# DA14682 register map
Vendor: Dialog; Series: DA14682; File version: 1.2
CPU: CM0 r1p0, little endian, MPU, FPU, 3 interrupt priority bits
Registers are 16-bit, read-write, reset 0x0 unless marked. A register's access mark holds for its fields unless they carry their own. Offsets are from the block's base; [hi:lo] are bit positions; lines under a group give offsets from that group; {n}, {i} and the like mark numbered series; 'fields as' and 'values as' point back to an identical list.

## KBSCAN — KBSCAN registers
Base 0x50001600
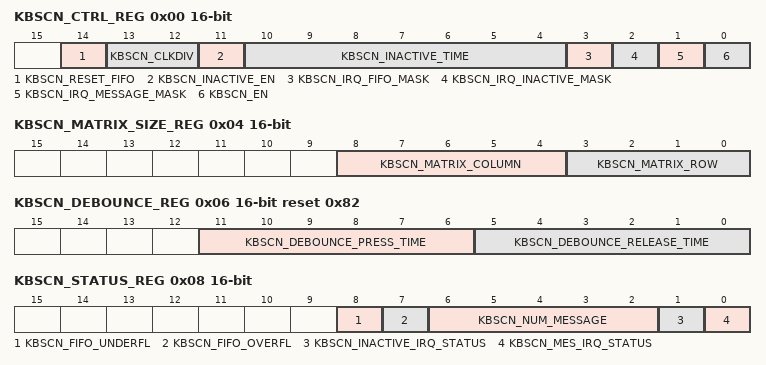
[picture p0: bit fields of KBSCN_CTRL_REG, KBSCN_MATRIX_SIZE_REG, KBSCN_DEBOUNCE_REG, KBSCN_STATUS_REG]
0x00 KBSCN_CTRL_REG — Keyboard scanner control register
  [14] KBSCN_RESET_FIFO wo — '1' reset fifo, read always '0'
  [13:12] KBSCN_CLKDIV — Defines keyboard clk. "00" div/1, "01" div/4, "10" div/16, "11" div/64
  [11] KBSCN_INACTIVE_EN — '1' After inactive time the keyboard scanner stops the key maxtrix scan
  [10:4] KBSCN_INACTIVE_TIME — Defines the inactive time in scan cycles. Value 0 is not allowed
  [3] KBSCN_IRQ_FIFO_MASK — '1' Enable IRQ for fifo over and under flow
  [2] KBSCN_IRQ_INACTIVE_MASK — '1' : Enable IRQ for inactive
  [1] KBSCN_IRQ_MESSAGE_MASK — '1' : Enable IRQ for message
  [0] KBSCN_EN — '1' : Enable keyboard scanner, Auto clear when inactive enable and inactive case
0x02 KBSCN_CTRL2_REG — Keyboard scanner control 2 register
  [15:0] KBSCN_ROW_ACTIVE_TIME — Define the row active time in keyboard clock cycles
0x04 KBSCN_MATRIX_SIZE_REG — Defines the number of rows and columns of the matrix
  [8:4] KBSCN_MATRIX_COLUMN — Defines the number of the columns of the keyboard matrix minus 1. Zero means number of columns 1
  [3:0] KBSCN_MATRIX_ROW — Defines the number of the rows of the keyboard matrix minus 1. Zero means number of rows 1
0x06 KBSCN_DEBOUNCE_REG reset 0x82 — Defines the debounce time for key press and release
  [11:6] KBSCN_DEBOUNCE_PRESS_TIME — Defines the press debounce time in cycles of full matrix scan. One means no debounce, zero is reserved
  [5:0] KBSCN_DEBOUNCE_RELEASE_TIME — Defines the press debounce time in cycles of full matrix scan. One means no debounce, zero is reserved
0x08 KBSCN_STATUS_REG — keyboard scanner Interrupt status register
  [8] KBSCN_FIFO_UNDERFL ro — '1' Fifo Underflow occurred
  [7] KBSCN_FIFO_OVERFL ro — '1' Fifo Overflow occurred
  [6:2] KBSCN_NUM_MESSAGE ro — Defines how many messages there are in the fifo.
  [1] KBSCN_INACTIVE_IRQ_STATUS ro — There is no keyboard activity for a predefined time
  [0] KBSCN_MES_IRQ_STATUS ro — There is at least one last message in the fifo.
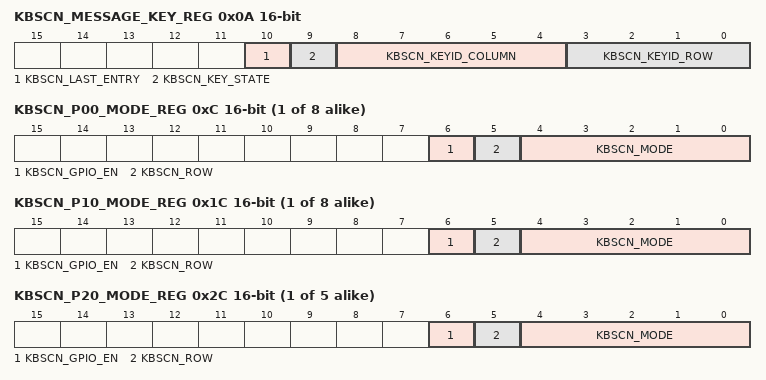
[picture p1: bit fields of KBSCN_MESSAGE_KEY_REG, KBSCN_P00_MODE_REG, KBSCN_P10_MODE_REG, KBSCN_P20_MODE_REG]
0x0A KBSCN_MESSAGE_KEY_REG — Returns a key message from the message queue
  [10] KBSCN_LAST_ENTRY ro — '1' : this message is the last of the group message, else '0'. When '1' bits 9:0 are all '1'
  [9] KBSCN_KEY_STATE ro — '0' : New key state is release '1' : New key state is press
  [8:4] KBSCN_KEYID_COLUMN ro — Defines the column id of key
  [3:0] KBSCN_KEYID_ROW ro — Defines the row id of key
{0xC+2i} KBSCN_P{i:02}_MODE_REG (i=0..7) — Defines the keyboard mode for P{i:02}
  [6] KBSCN_GPIO_EN — '1' GPIO is enable for row or column
  [5] KBSCN_ROW — '1' GPIO is row, '0' GPIO is column
  [4:0] KBSCN_MODE — Defines the row/column index that has to be connected
{0x8+2i} KBSCN_P{i}_MODE_REG (i=10..17) — Defines the keyboard mode for P{i}
  fields as KBSCN_P00_MODE_REG
{0x4+2i} KBSCN_P{i}_MODE_REG (i=20..24) — Defines the keyboard mode for P{i}
  fields as KBSCN_P00_MODE_REG
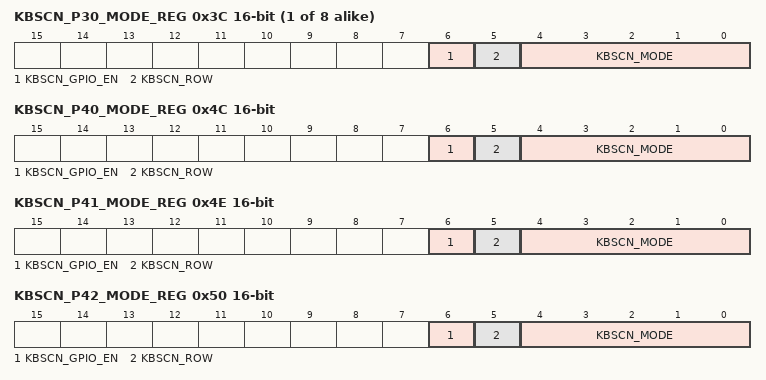
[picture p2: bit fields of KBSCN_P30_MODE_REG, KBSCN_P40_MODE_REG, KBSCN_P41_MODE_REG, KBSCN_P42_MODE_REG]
{0x0+2i} KBSCN_P{i}_MODE_REG (i=30..37) — Defines the keyboard mode for P{i}
  fields as KBSCN_P00_MODE_REG
0x4C KBSCN_P40_MODE_REG — Defines the keyboard mode for P40
  fields as KBSCN_P00_MODE_REG
0x4E KBSCN_P41_MODE_REG — Defines the keyboard mode for P41
  fields as KBSCN_P00_MODE_REG
0x50 KBSCN_P42_MODE_REG — Defines the keyboard mode for P42
  fields as KBSCN_P00_MODE_REG
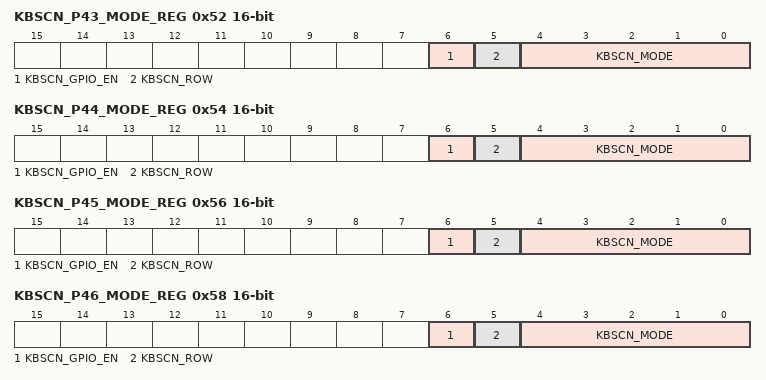
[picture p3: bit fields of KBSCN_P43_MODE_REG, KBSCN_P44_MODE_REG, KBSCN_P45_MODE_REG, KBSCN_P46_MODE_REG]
0x52 KBSCN_P43_MODE_REG — Defines the keyboard mode for P43
  fields as KBSCN_P00_MODE_REG
0x54 KBSCN_P44_MODE_REG — Defines the keyboard mode for P44
  fields as KBSCN_P00_MODE_REG
0x56 KBSCN_P45_MODE_REG — Defines the keyboard mode for P45
  fields as KBSCN_P00_MODE_REG
0x58 KBSCN_P46_MODE_REG — Defines the keyboard mode for P46
  fields as KBSCN_P00_MODE_REG
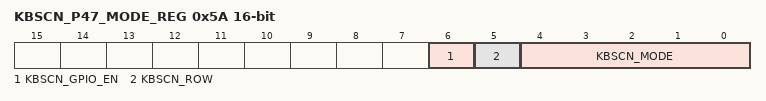
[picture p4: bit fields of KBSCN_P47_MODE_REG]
0x5A KBSCN_P47_MODE_REG — Defines the keyboard mode for P47
  fields as KBSCN_P00_MODE_REG
